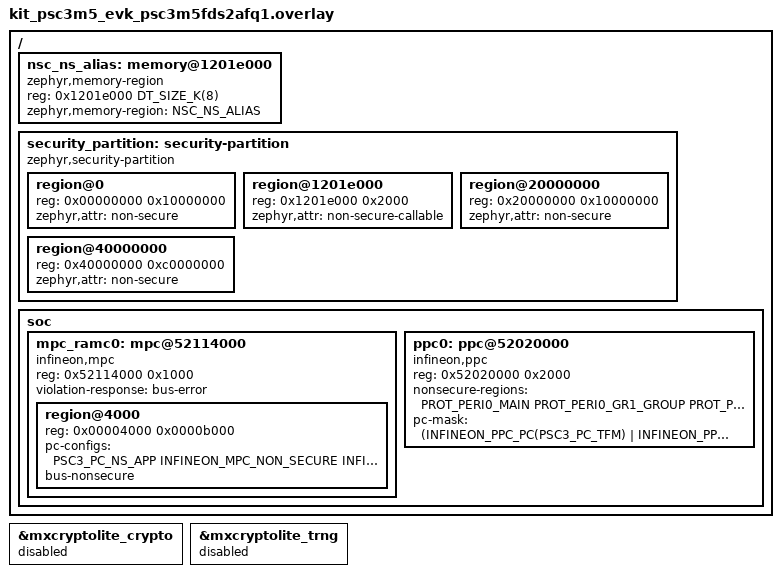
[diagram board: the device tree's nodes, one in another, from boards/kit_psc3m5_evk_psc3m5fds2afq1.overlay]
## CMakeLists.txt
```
# SPDX-FileCopyrightText: Copyright (c) 2026 Infineon Technologies AG,
# SPDX-FileCopyrightText: or an affiliate of Infineon Technologies AG. All rights reserved.
#
# SPDX-License-Identifier: Apache-2.0

cmake_minimum_required(VERSION 3.20.0)
find_package(Zephyr REQUIRED HINTS $ENV{ZEPHYR_BASE})
project(secure_call_tz_s)

target_sources(app PRIVATE
    src/main.c
    src/secure_impl.c
)
```

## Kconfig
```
# SPDX-FileCopyrightText: Copyright (c) 2026 Infineon Technologies AG,
# SPDX-FileCopyrightText: or an affiliate of Infineon Technologies AG. All rights reserved.
#
# SPDX-License-Identifier: Apache-2.0

mainmenu "Secure Call TrustZone Secure Image"

config SECURE_CALL_NS_IMAGE_BASE
	hex "Non-Secure image vector table base (Non-Secure alias)"
	help
	  Address of the Non-Secure image's vector table in the Non-Secure
	  address alias. The Secure image points the Non-Secure VTOR here and
	  reads the Non-Secure initial SP/PC from it. Board-specific; set in the
	  per-board Kconfig fragment.

config SECURE_CALL_NS_IMAGE_BASE_SECURE_ALIAS
	hex "Non-Secure image vector table base (Secure alias)"
	help
	  The same physical location as SECURE_CALL_NS_IMAGE_BASE but reached
	  through the Secure address alias. The Secure image reads the Non-Secure
	  vector table through this alias before the MPC restricts Secure access
	  to the region.

source "Kconfig.zephyr"
```

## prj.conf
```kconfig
# SPDX-FileCopyrightText: Copyright (c) 2026 Infineon Technologies AG,
# SPDX-FileCopyrightText: or an affiliate of Infineon Technologies AG. All rights reserved.
#
# SPDX-License-Identifier: Apache-2.0

# Secure image: exposes __secure_call entry functions and boots the NS image.
CONFIG_MULTITHREADING=n
CONFIG_APPLICATION_DEFINED_SYSCALL=y
CONFIG_ARM_FIRMWARE_HAS_SECURE_CALLS=y
CONFIG_ARM_SAU=y
```

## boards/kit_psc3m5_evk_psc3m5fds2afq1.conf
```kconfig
# SPDX-FileCopyrightText: Copyright (c) 2026 Infineon Technologies AG,
# SPDX-FileCopyrightText: or an affiliate of Infineon Technologies AG. All rights reserved.
#
# SPDX-License-Identifier: Apache-2.0

CONFIG_ARM_NSC_REGION_BASE_ADDRESS=0x1201e000
CONFIG_ARM_NSC_REGION_IN_NS_ALIAS=y
CONFIG_INFINEON_MPC=y
CONFIG_INFINEON_PPC=y

# PSC3 is Infineon silicon (BXNS raises INVTRAN): enter NS via the arch SVC flow.
CONFIG_ARM_SECURE_DOMAIN_ENTRY_SVC=y

# NS image vector table: NS flash alias 0x02010000 (Secure alias 0x12010000).
CONFIG_SECURE_CALL_NS_IMAGE_BASE=0x02010000
CONFIG_SECURE_CALL_NS_IMAGE_BASE_SECURE_ALIAS=0x12010000
```

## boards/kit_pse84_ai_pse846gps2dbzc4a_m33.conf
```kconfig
# SPDX-FileCopyrightText: Copyright (c) 2026 Infineon Technologies AG,
# SPDX-FileCopyrightText: or an affiliate of Infineon Technologies AG. All rights reserved.
#
# SPDX-License-Identifier: Apache-2.0

CONFIG_ARM_NSC_REGION_BASE_ADDRESS=0x18110000
CONFIG_ARM_NSC_REGION_IN_NS_ALIAS=y
CONFIG_INFINEON_MPC=y
CONFIG_INFINEON_PPC=y

# NS image vector table: m33_xip flash at NS alias 0x08340400 (Secure alias 0x18340400).
CONFIG_SECURE_CALL_NS_IMAGE_BASE=0x08340400
CONFIG_SECURE_CALL_NS_IMAGE_BASE_SECURE_ALIAS=0x18340400
```

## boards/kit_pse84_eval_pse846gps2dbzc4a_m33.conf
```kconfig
# SPDX-FileCopyrightText: Copyright (c) 2026 Infineon Technologies AG,
# SPDX-FileCopyrightText: or an affiliate of Infineon Technologies AG. All rights reserved.
#
# SPDX-License-Identifier: Apache-2.0

# The pse84 secure image drives the mxcrypto MFD and its TRNG entropy driver,
# which use k_mutex; keep the scheduler (the shared prj.conf disables it).
CONFIG_MULTITHREADING=y

CONFIG_ARM_NSC_REGION_BASE_ADDRESS=0x18110000
CONFIG_ARM_NSC_REGION_IN_NS_ALIAS=y
CONFIG_INFINEON_MPC=y
CONFIG_INFINEON_PPC=y

# NS image vector table: m33_xip flash at NS alias 0x08340400 (Secure alias 0x18340400).
CONFIG_SECURE_CALL_NS_IMAGE_BASE=0x08340400
CONFIG_SECURE_CALL_NS_IMAGE_BASE_SECURE_ALIAS=0x18340400
```

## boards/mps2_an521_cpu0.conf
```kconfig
# SPDX-FileCopyrightText: Copyright (c) 2026 Infineon Technologies AG,
# SPDX-FileCopyrightText: or an affiliate of Infineon Technologies AG. All rights reserved.
#
# SPDX-License-Identifier: Apache-2.0

CONFIG_ARM_NSC_REGION_BASE_ADDRESS=0x0001E000
CONFIG_ARM_NSC_REGION_IN_NS_ALIAS=y
CONFIG_ARM_TZ_MPC=y
CONFIG_ARM_SSE200_SPCTRL=y

# NS image vector table: code SRAM at NS alias 0x00100000 (Secure alias 0x10100000).
CONFIG_SECURE_CALL_NS_IMAGE_BASE=0x00100000
CONFIG_SECURE_CALL_NS_IMAGE_BASE_SECURE_ALIAS=0x10100000
```

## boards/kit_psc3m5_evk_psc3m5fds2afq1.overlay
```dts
/*
 * SPDX-FileCopyrightText: Copyright (c) 2026 Infineon Technologies AG,
 * SPDX-FileCopyrightText: or an affiliate of Infineon Technologies AG. All rights reserved.
 *
 * SPDX-License-Identifier: Apache-2.0
 *
 * PSC3 Secure image: SAU region table, the CMSE veneer (NSC) window, and the
 * MPC/PPC nodes that hand SRAM and the console SCB to the Non-Secure
 * world before arch_secure_domain_swap().
 *
 * PSC3 aliasing: Secure alias = Non-Secure alias | 0x10000000
 *   flash  NS 0x02000000  / S 0x12000000
 *   SRAM   NS 0x24000000  / S 0x34000000
 */

#include <zephyr/dt-bindings/mpc/infineon-mpc.h>
#include <zephyr/dt-bindings/ppc/infineon-ppc.h>
#include <zephyr/dt-bindings/ppc/infineon-psc3-ppc.h>

/ {
	/*
	 * Linker MEMORY region for the CMSE SG veneers (.gnu.sgstubs), placed at
	 * the end of the 128K Secure flash slot and marked NSC by the SAU below.
	 */
	nsc_ns_alias: memory@1201e000 {
		compatible = "zephyr,memory-region";
		reg = <0x1201e000 DT_SIZE_K(8)>;
		zephyr,memory-region = "NSC_NS_ALIAS";
	};

	/*
	 * SAU region table (see arch_security_partition_configure()).
	 *
	 * The Non-Secure flash alias (0x00000000-0x0FFFFFFF) and SRAM alias
	 * (0x20000000-0x2FFFFFFF) are NS; the peripheral space (0x40000000+) is
	 * NS; the Secure flash defaults Secure except the explicit NSC veneer
	 * window at CONFIG_ARM_NSC_REGION_BASE_ADDRESS.
	 */
	security_partition: security-partition {
		compatible = "zephyr,security-partition";
		#address-cells = <1>;
		#size-cells = <1>;

		region@0 {
			reg = <0x00000000 0x10000000>;
			zephyr,attr = "non-secure";
		};
		region@1201e000 {
			reg = <0x1201e000 0x2000>;
			zephyr,attr = "non-secure-callable";
		};
		region@20000000 {
			reg = <0x20000000 0x10000000>;
			zephyr,attr = "non-secure";
		};
		region@40000000 {
			reg = <0x40000000 0xc0000000>;
			zephyr,attr = "non-secure";
		};
	};

	soc {
		/* RAMC0 SRAM MPC: hand the Non-Secure SRAM bank to NS. */
		mpc_ramc0: mpc@52114000 {
			compatible = "infineon,mpc";
			reg = <0x52114000 0x1000>;
			violation-response = "bus-error";
			#address-cells = <1>;
			#size-cells = <1>;
			status = "okay";

			/* NS SRAM at 0x24004000 = offset 0x4000, size 44K: NS RW. */
			region@4000 {
				reg = <0x00004000 0x0000b000>;
				pc-configs = <PSC3_PC_NS_APP INFINEON_MPC_NON_SECURE
					      INFINEON_MPC_ACCESS_RW>;
				bus-nonsecure;
			};
		};

		/*
		 * PERI0 PPC: open only the curated regions the Non-Secure image
		 * needs — the console SCB3 (uart3) and its clock/group path.  A
		 * blanket sweep bus-faults on SROM-locked slots.
		 */
		ppc0: ppc@52020000 {
			compatible = "infineon,ppc";
			reg = <0x52020000 0x2000>;
			nonsecure-regions = <PROT_PERI0_MAIN
					     PROT_PERI0_GR1_GROUP
					     PROT_PERI0_GR2_GROUP
					     PROT_PERI0_GR3_GROUP
					     PROT_PERI0_GR4_GROUP
					     PROT_PERI0_GR5_GROUP
					     PROT_PERI0_PERI_PCLK0_MAIN
					     PROT_SCB3>;
			pc-mask = <(INFINEON_PPC_PC(PSC3_PC_TFM) |
				    INFINEON_PPC_PC(PSC3_PC_NS_APP) |
				    INFINEON_PPC_PC(PSC3_PC_DAP))>;
			status = "okay";
		};
	};
};

&mxcryptolite_crypto {
	status = "disabled";
};

&mxcryptolite_trng {
	status = "disabled";
};
```

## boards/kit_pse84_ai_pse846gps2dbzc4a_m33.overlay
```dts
/*
 * SPDX-FileCopyrightText: Copyright (c) 2026 Infineon Technologies AG,
 * SPDX-FileCopyrightText: or an affiliate of Infineon Technologies AG. All rights reserved.
 *
 * SPDX-License-Identifier: Apache-2.0
 *
 * Place .gnu.sgstubs at 0x18110000 (CBUS S-alias flash).
 * BUILD_OUTPUT_ADJUST_LMA +0x48000000 maps this to SAHB 0x60110000 for flashing.
 * The SAU marks this address NSC so NS callers can BLXNS to 0x18110001.
 */

/ {

	/*
	 * Linker MEMORY region that holds the CMSE SG veneers (.gnu.sgstubs).
	 * Sized to match the SAU NSC window below (region@18110000, 0x2000): the
	 * veneers must stay within the NSC-marked range to be callable from NS.
	 * The handful of __secure_call stubs are tiny, so 8K is ample headroom.
	 */
	nsc_ns_alias: memory@18110000 {
		compatible = "zephyr,memory-region";
		reg = <0x18110000 DT_SIZE_K(8)>;
		zephyr,memory-region = "NSC_NS_ALIAS";
	};

	/*
	 * SAU region table (see arch_security_partition_configure()).
	 *
	 * All of the CBUS NS flash alias (0x00000000-0x0FFFFFFF) is NS; the CBUS
	 * S range defaults to Secure except the explicit NSC veneer window at
	 * CONFIG_ARM_NSC_REGION_BASE_ADDRESS (0x18110000). SRAM NS alias and the
	 * peripheral/upper address space are NS.
	 */
	security_partition: security-partition {
		compatible = "zephyr,security-partition";
		#address-cells = <1>;
		#size-cells = <1>;

		region@0 {
			reg = <0x00000000 0x10000000>;
			zephyr,attr = "non-secure";
		};
		region@18110000 {
			reg = <0x18110000 0x2000>;
			zephyr,attr = "non-secure-callable";
		};
		region@20000000 {
			reg = <0x20000000 0x10000000>;
			zephyr,attr = "non-secure";
		};
		region@40000000 {
			reg = <0x40000000 0xc0000000>;
			zephyr,attr = "non-secure";
		};
	};
};
```

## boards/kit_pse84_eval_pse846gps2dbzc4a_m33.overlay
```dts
/*
 * SPDX-FileCopyrightText: Copyright (c) 2026 Infineon Technologies AG,
 * SPDX-FileCopyrightText: or an affiliate of Infineon Technologies AG. All rights reserved.
 *
 * SPDX-License-Identifier: Apache-2.0
 *
 * Place .gnu.sgstubs at 0x18110000 (CBUS S-alias flash).
 * BUILD_OUTPUT_ADJUST_LMA +0x48000000 maps this to SAHB 0x60110000 for flashing.
 * The SAU marks this address NSC so NS callers can BLXNS to 0x18110001.
 */

/ {
	/*
	 * Linker MEMORY region that holds the CMSE SG veneers (.gnu.sgstubs).
	 * Sized to match the SAU NSC window below (region@18110000, 0x2000): the
	 * veneers must stay within the NSC-marked range to be callable from NS.
	 * The handful of __secure_call stubs are tiny, so 8K is ample headroom.
	 */
	nsc_ns_alias: memory@18110000 {
		compatible = "zephyr,memory-region";
		reg = <0x18110000 DT_SIZE_K(8)>;
		zephyr,memory-region = "NSC_NS_ALIAS";
	};

	/*
	 * SAU region table (see arch_security_partition_configure()).
	 *
	 * All of the CBUS NS flash alias (0x00000000-0x0FFFFFFF) is NS; the CBUS
	 * S range defaults to Secure except the explicit NSC veneer window at
	 * CONFIG_ARM_NSC_REGION_BASE_ADDRESS (0x18110000). SRAM NS alias and the
	 * peripheral/upper address space are NS.
	 */
	security_partition: security-partition {
		compatible = "zephyr,security-partition";
		#address-cells = <1>;
		#size-cells = <1>;

		region@0 {
			reg = <0x00000000 0x10000000>;
			zephyr,attr = "non-secure";
		};
		region@18110000 {
			reg = <0x18110000 0x2000>;
			zephyr,attr = "non-secure-callable";
		};
		region@20000000 {
			reg = <0x20000000 0x10000000>;
			zephyr,attr = "non-secure";
		};
		region@40000000 {
			reg = <0x40000000 0xc0000000>;
			zephyr,attr = "non-secure";
		};
	};
};
```

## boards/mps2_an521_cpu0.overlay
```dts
/*
 * SPDX-FileCopyrightText: Copyright (c) 2026 Infineon Technologies AG,
 * SPDX-FileCopyrightText: or an affiliate of Infineon Technologies AG. All rights reserved.
 *
 * SPDX-License-Identifier: Apache-2.0
 *
 * Add a linker MEMORY region covering the NS-alias of SSRAM1 so that
 * .gnu.sgstubs can be placed at 0x0001e000 (CONFIG_ARM_NSC_REGION_BASE_ADDRESS)
 * without triggering a "cannot move location counter backwards" error.
 *
 * The NS alias (0x00000000-0x003FFFFF) and the S alias (0x10000000-0x103FFFFF)
 * map to the same physical SSRAM1. This overlay only creates the named MEMORY
 * region; it does not change zephyr,flash or zephyr,sram.
 *
 * MPC nodes configure the QEMU mps2-an521 Memory Protection Controllers:
 *   mpc_sram1 (0x58007000): controls code SRAM (NS alias 0x00000000-0x003FFFFF)
 *   mpc_sram2 (0x58008000): controls data SRAM (NS alias 0x28000000-0x281FFFFF)
 *
 * nonsecure-ranges encodes (offset, size) pairs relative to each bank's base.
 * The NS code and data partitions both start at offset 0x100000 within their
 * respective SRAM banks and are each 512 KB in size.
 */

/ {
	nsc_ns_alias: memory@0 {
		compatible = "zephyr,memory-region", "mmio-sram";
		reg = <0x0 DT_SIZE_K(128)>;
		zephyr,memory-region = "NSC_NS_ALIAS";
	};

	/*
	 * SAU region table (see arch_security_partition_configure()).
	 *
	 * The regions must NOT overlap: QEMU's v8m_security_lookup treats an
	 * address matching two regions as Secure, which breaks the SG stubs. The
	 * NS code region starts at 0x00100000, leaving 0x0-0xFFFFF uncovered so the
	 * NSC veneer window at CONFIG_ARM_NSC_REGION_BASE_ADDRESS (0x0001E000) is
	 * covered only by the NSC region.
	 */
	security_partition: security-partition {
		compatible = "zephyr,security-partition";
		#address-cells = <1>;
		#size-cells = <1>;

		region@100000 {
			reg = <0x00100000 0x0f000000>;
			zephyr,attr = "non-secure";
		};
		region@20000000 {
			reg = <0x20000000 0x10000000>;
			zephyr,attr = "non-secure";
		};
		region@40000000 {
			reg = <0x40000000 0x10000000>;
			zephyr,attr = "non-secure";
		};
		region@1e000 {
			reg = <0x0001e000 0x2000>;
			zephyr,attr = "non-secure-callable";
		};
	};

	/*
	 * SSE-200 SPCTRL: set CODENSC (bit 0) so the IDAU marks code SRAM as
	 * NSC-capable. Required for SG veneers in the NS-alias code SRAM to
	 * survive QEMU's v8m_security_lookup without being stripped to plain NS.
	 */
	spctrl: spctrl@50080000 {
		compatible = "arm,sse-200-spctrl";
		reg = <0x50080000 0x1000>;
		nsccfg = <0x1>;
		/* Grant NS access to all APB expansion PPC1 ports (UARTs 0-4 etc.) */
		apbnsppcexp1-ns-mask = <0xFFFFFFFF>;
		status = "okay";
	};

	/*
	 * QEMU mps2-an521 TZ-MPC peripherals on the Secure AHB bus (0x58000000).
	 * These are not in the upstream AN521 DTS; we define them here so the
	 * arm_tz_mpc driver can program the NS partitions from the child nodes.
	 */
	mpc_sram1: mpc@58007000 {
		compatible = "arm,tz-mpc";
		reg = <0x58007000 0x1000>;
		#address-cells = <1>;
		#size-cells = <1>;
		status = "okay";

		/* NS code partition: offset 0x100000, 512 KB */
		region@100000 {
			reg = <0x00100000 0x00080000>;
		};
	};

	mpc_sram2: mpc@58008000 {
		compatible = "arm,tz-mpc";
		reg = <0x58008000 0x1000>;
		#address-cells = <1>;
		#size-cells = <1>;
		status = "okay";

		/* NS data partition: offset 0x100000 within data SRAM, 512 KB */
		region@100000 {
			reg = <0x00100000 0x00080000>;
		};
	};
};
```

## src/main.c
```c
/*
 * SPDX-FileCopyrightText: Copyright (c) 2026 Infineon Technologies AG,
 * SPDX-FileCopyrightText: or an affiliate of Infineon Technologies AG. All rights reserved.
 *
 * SPDX-License-Identifier: Apache-2.0
 *
 * Secure-image entry point for the __secure_call TrustZone integration test.
 */

#include <zephyr/kernel.h>
#include <zephyr/devicetree.h>
#include <zephyr/arch/security_partition.h>
#include <zephyr/arch/secure_domain.h>
#if defined(CONFIG_MPC)
#include <zephyr/drivers/mpc/mpc.h>
#endif
#if defined(CONFIG_PPC)
#include <zephyr/drivers/ppc/ppc.h>
#endif
#include <cmsis_core.h>

/*
 * Non-Secure image vector table location (board-specific, from Kconfig):
 *   NS_IMAGE_BASE     — Non-Secure alias; the Secure image points the NS VTOR
 *                       here and reads the NS initial SP/PC from it.
 *   NS_IMAGE_BASE_SA  — Secure alias of the same location; used to read the NS
 *                       vector table before the MPC restricts Secure access.
 */
#define NS_IMAGE_BASE    CONFIG_SECURE_CALL_NS_IMAGE_BASE
#define NS_IMAGE_BASE_SA CONFIG_SECURE_CALL_NS_IMAGE_BASE_SECURE_ALIAS

/*
 * Build the SAU region table from the board's "zephyr,security-partition" node.
 * The zephyr,attr enum is ordered to match enum arch_security_attr, so its
 * DT_ENUM_IDX maps straight onto the .attr field (asserted below).
 */
#define SAU_REGION_ENTRY(node)                                                                     \
	{                                                                                          \
		.base = DT_REG_ADDR(node),                                                         \
		.size = DT_REG_SIZE(node),                                                         \
		.attr = (enum arch_security_attr)DT_ENUM_IDX(node, zephyr_attr),                   \
	},

static void sau_setup(void)
{
	static const struct arch_security_region regions[] = {
		DT_FOREACH_CHILD(DT_NODELABEL(security_partition), SAU_REGION_ENTRY)};

	BUILD_ASSERT((int)ARCH_SECURITY_ATTR_S == 0);
	BUILD_ASSERT((int)ARCH_SECURITY_ATTR_NS == 1);
	BUILD_ASSERT((int)ARCH_SECURITY_ATTR_NSC == 2);

	arch_security_partition_configure(regions, ARRAY_SIZE(regions));
	arch_security_partition_enable();
	__DSB();
	__ISB();
}

int main(void)
{
	/* Read NS vector table via S alias BEFORE MPC blocks Secure access to those blocks. */
	volatile uint32_t *ns_vt = (volatile uint32_t *)(uintptr_t)NS_IMAGE_BASE_SA;
	uint32_t ns_sp = ns_vt[0];
	uint32_t ns_pc = ns_vt[1];

	printk("S: NS image pc=0x%08x sp=0x%08x\n", ns_pc, ns_sp);

#if defined(CONFIG_MPC)
	printk("S: configuring MPC\n");
	mpc_configure_all();
	__DSB();
	__ISB();
#endif

	printk("S: configuring SAU\n");
	sau_setup();

	/*
	 * The Non-Secure image, as a secure domain to hand control to: entry/stack
	 * come from its vector table, its vector-table base is installed as the NS
	 * VTOR, and it is granted FPU access (the NS image is built hard-float).
	 */
	const struct arch_secure_domain ns_domain = {
		.entry = ns_pc,
		.stack = ns_sp,
		.vector_table = NS_IMAGE_BASE,
		.flags = ARCH_SECURE_DOMAIN_ENABLE_FPU,
	};

#if defined(CONFIG_PPC)
	/*
	 * Grant the NS protection context access to the peripherals it needs (the
	 * shared console among them) via the PPC driver (DT-driven; on PSE84 the
	 * curated "M33_M55" region list, on the SSE-200 the APBNSPPCEXP1 mask).
	 *
	 * The console is shared with the Secure image: once it becomes non-secure,
	 * any Secure access to its secure alias bus-faults. This MUST be the last
	 * Secure printk — arch_secure_domain_swap() below touches only CPU/system
	 * registers (and the MXCM33 VTOR shadow on PSE84), never the shared console.
	 */
	printk("S: configuring PPC then entering NS (no more S output)\n");
	ppc_configure_ns_all();
	__DSB();
#endif

	/*
	 * Hand control to the Non-Secure domain (does not return). The entry
	 * mechanism — BXNS, or the SVC exception-return flow for silicon with the
	 * INVTRAN deviation (CONFIG_ARM_SECURE_DOMAIN_ENTRY_SVC) — is chosen by
	 * the arch backend of arch_secure_domain_swap().
	 */
	arch_secure_domain_swap(&ns_domain);
	__builtin_unreachable();
}
```

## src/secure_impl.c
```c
/*
 * SPDX-FileCopyrightText: Copyright (c) 2026 Infineon Technologies AG,
 * SPDX-FileCopyrightText: or an affiliate of Infineon Technologies AG. All rights reserved.
 *
 * SPDX-License-Identifier: Apache-2.0
 *
 * Secure-side implementations for the TZ integration test.
 *
 * z_secure_vrfy_*  – called by the generated z_secure_mrsh_* entry functions;
 *                    validates NS pointers before touching them.
 * z_secure_impl_*  – the actual TEE-side business logic.
 */

#include <stdint.h>
#include <stddef.h>
#include <zephyr/internal/secure_call_handler.h>

int z_secure_impl_sc_add(int a, int b)
{
	return a + b;
}

void z_secure_impl_sc_fill(uint8_t *buf, size_t len)
{
	for (size_t i = 0; i < len; i++) {
		buf[i] = (uint8_t)i;
	}
}

int z_secure_impl_sc_nop(void)
{
	return 42;
}

int z_secure_vrfy_sc_add(int a, int b)
{
	/* Scalar args — no pointer validation needed */
	return z_secure_impl_sc_add(a, b);
}

void z_secure_vrfy_sc_fill(uint8_t *buf, size_t len)
{
	/* Validate that the entire buffer is in NS-accessible read-write memory */
	Z_SECURE_MEMORY_WRITE(buf, len);
	z_secure_impl_sc_fill(buf, len);
}

int z_secure_vrfy_sc_nop(void)
{
	return z_secure_impl_sc_nop();
}
```

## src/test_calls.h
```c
/*
 * SPDX-FileCopyrightText: Copyright (c) 2026 Infineon Technologies AG,
 * SPDX-FileCopyrightText: or an affiliate of Infineon Technologies AG. All rights reserved.
 *
 * SPDX-License-Identifier: Apache-2.0
 *
 * Scanned by parse_secure_calls.py (via APPLICATION_DEFINED_SYSCALL) so that
 * the S-side z_secure_mrsh_* entry functions are generated and compiled in.
 */

#ifndef TESTS_SECURE_CALL_TZ_S_TEST_CALLS_H_
#define TESTS_SECURE_CALL_TZ_S_TEST_CALLS_H_

#include <stdint.h>
#include <zephyr/toolchain.h>

__secure_call int sc_add(int a, int b);
__secure_call void sc_fill(uint8_t *buf, size_t len);
__secure_call int sc_nop(void);

#endif /* TESTS_SECURE_CALL_TZ_S_TEST_CALLS_H_ */
```
